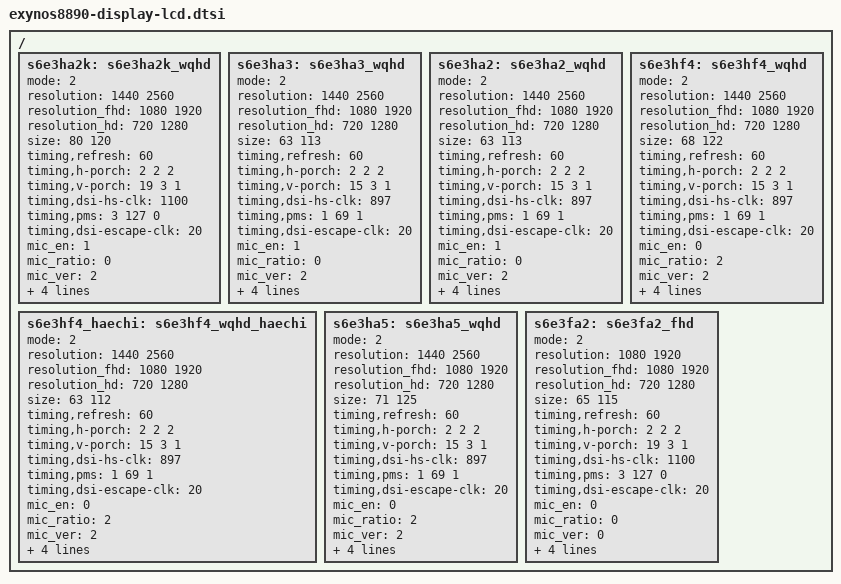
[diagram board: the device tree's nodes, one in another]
/*
 * SAMSUNG LCD Panel Device Tree Source
 *
 * Copyright (c) 2015 Samsung Electronics Co., Ltd.
 *		http://www.samsung.com
 *
 * This program is free software; you can redistribute it and/or modify
 * it under the terms of the GNU General Public License version 2 as
 * published by the Free Software Foundation.
*/

/ {
	s6e3ha2k: s6e3ha2k_wqhd {
		mode = <2>;		/* 0: video mode, 1: DP command mode, 2: MIPI command mode */
		resolution = <1440 2560>;
		resolution_fhd = <1080 1920>;
		resolution_hd = <720 1280>;
		size = <80 120>;
		timing,refresh = <60>;
		timing,h-porch = <2 2 2>;
		timing,v-porch = <19 3 1>;
		timing,dsi-hs-clk = <1100>;
		timing,pms = <3 127 0>;
		timing,dsi-escape-clk = <20>;
		mic_en = <1>;		/* 0: Disable, 1: Enable */
		mic_ratio = <0>;	/* 0: 1/2 mic, 1: 1/3 mic */
		mic_ver = <2>;		/* 0: mic v1.1, 1: v1.2, 2: v2.0 */
		type_of_ddi = <0>;	/* 0: Samsung Mobile, 1: MAGNA, 2: Normal(Etc) */
		dsc_en = <0>;		/* 0: Disable, 1: Enable */
		dsc_cnt = <0>;		/* used DSC count */
		dsc_slice_num = <0>;	/* count of dsc slice */
	};

	s6e3ha3: s6e3ha3_wqhd {
		mode = <2>;		/* 0: video mode, 1: DP command mode, 2: MIPI command mode */
		resolution = <1440 2560>;
		resolution_fhd = <1080 1920>;
		resolution_hd = <720 1280>;
		size = <63 113>;
		timing,refresh = <60>;
		timing,h-porch = <2 2 2>;
		timing,v-porch = <15 3 1>;
		timing,dsi-hs-clk = <897>;
		timing,pms = <1 69 1>;
		timing,dsi-escape-clk = <20>;
		mic_en = <1>;		/* 0: Disable, 1: Enable */
		mic_ratio = <0>;	/* 0: 1/2 mic, 1: 1/3 mic */
		mic_ver = <2>;		/* 0: mic v1.1, 1: v1.2, 2: v2.0 */
		type_of_ddi = <0>;	/* 0: Samsung Mobile, 1: MAGNA, 2: Normal(Etc) */
		dsc_en = <0>;		/* 0: Disable, 1: Enable */
		dsc_cnt = <0>;		/* used DSC count */
		dsc_slice_num = <0>;	/* count of dsc slice */
	};

	s6e3ha2: s6e3ha2_wqhd {
		mode = <2>;		/* 0: video mode, 1: DP command mode, 2: MIPI command mode */
		resolution = <1440 2560>;
		resolution_fhd = <1080 1920>;
		resolution_hd = <720 1280>;
		size = <63 113>;
		timing,refresh = <60>;
		timing,h-porch = <2 2 2>;
		timing,v-porch = <15 3 1>;
		timing,dsi-hs-clk = <897>;
		timing,pms = <1 69 1>;
		timing,dsi-escape-clk = <20>;
		mic_en = <1>;		/* 0: Disable, 1: Enable */
		mic_ratio = <0>;	/* 0: 1/2 mic, 1: 1/3 mic */
		mic_ver = <2>;		/* 0: mic v1.1, 1: v1.2, 2: v2.0 */
		type_of_ddi = <0>;	/* 0: Samsung Mobile, 1: MAGNA, 2: Normal(Etc) */
		dsc_en = <0>;		/* 0: Disable, 1: Enable */
		dsc_cnt = <0>;		/* used DSC count */
		dsc_slice_num = <0>;	/* count of dsc slice */
	};

	s6e3hf4: s6e3hf4_wqhd {
		mode = <2>;		/* 0: video mode, 1: DP command mode, 2: MIPI command mode */
		resolution = <1440 2560>;
		resolution_fhd = <1080 1920>;
		resolution_hd = <720 1280>;
		size = <68 122>;
		timing,refresh = <60>;
		timing,h-porch = <2 2 2>;
		timing,v-porch = <15 3 1>;
		timing,dsi-hs-clk = <897>;
		timing,pms = <1 69 1>;
		timing,dsi-escape-clk = <20>;
		mic_en = <0>;		/* 0: Disable, 1: Enable */
		mic_ratio = <2>;	/* 0: 1/2 mic, 1: 1/3 mic */
		mic_ver = <2>;		/* 0: mic v1.1, 1: v1.2, 2: v2.0 */
		type_of_ddi = <0>;	/* 0: Samsung Mobile, 1: MAGNA, 2: Normal(Etc) */
		dsc_en = <1>;		/* 0: Disable, 1: Enable */
		dsc_cnt = <2>;		/* used DSC count */
		dsc_slice_num = <4>;	/* count of dsc slice */
	};

	s6e3hf4_haechi: s6e3hf4_wqhd_haechi {
		mode = <2>;		/* 0: video mode, 1: DP command mode, 2: MIPI command mode */
		resolution = <1440 2560>;
		resolution_fhd = <1080 1920>;
		resolution_hd = <720 1280>;
		size = <63 112>;
		timing,refresh = <60>;
		timing,h-porch = <2 2 2>;
		timing,v-porch = <15 3 1>;
		timing,dsi-hs-clk = <897>;
		timing,pms = <1 69 1>;
		timing,dsi-escape-clk = <20>;
		mic_en = <0>;		/* 0: Disable, 1: Enable */
		mic_ratio = <2>;	/* 0: 1/2 mic, 1: 1/3 mic */
		mic_ver = <2>;		/* 0: mic v1.1, 1: v1.2, 2: v2.0 */
		type_of_ddi = <0>;	/* 0: Samsung Mobile, 1: MAGNA, 2: Normal(Etc) */
		dsc_en = <1>;		/* 0: Disable, 1: Enable */
		dsc_cnt = <2>;		/* used DSC count */
		dsc_slice_num = <4>;	/* count of dsc slice */
	};


	s6e3ha5: s6e3ha5_wqhd {
		mode = <2>;		/* 0: video mode, 1: DP command mode, 2: MIPI command mode */
		resolution = <1440 2560>;
		resolution_fhd = <1080 1920>;
		resolution_hd = <720 1280>;
		size = <71 125>;
		timing,refresh = <60>;
		timing,h-porch = <2 2 2>;
		timing,v-porch = <15 3 1>;
		timing,dsi-hs-clk = <897>;
		timing,pms = <1 69 1>;
		timing,dsi-escape-clk = <20>;
		mic_en = <0>;		/* 0: Disable, 1: Enable */
		mic_ratio = <2>;	/* 0: 1/2 mic, 1: 1/3 mic */
		mic_ver = <2>;		/* 0: mic v1.1, 1: v1.2, 2: v2.0 */
		type_of_ddi = <0>;	/* 0: Samsung Mobile, 1: MAGNA, 2: Normal(Etc) */
		dsc_en = <1>;		/* 0: Disable, 1: Enable */
		dsc_cnt = <2>;		/* used DSC count */
		dsc_slice_num = <2>;	/* count of dsc slice */
	};

	s6e3fa2: s6e3fa2_fhd {
		mode = <2>;		/* 0: video mode, 1: DP command mode, 2: MIPI command mode */
		resolution = <1080 1920>;
		resolution_fhd = <1080 1920>;
		resolution_hd = <720 1280>;
		size = <65 115>;
		timing,refresh = <60>;
		timing,h-porch = <2 2 2>;
		timing,v-porch = <19 3 1>;
		timing,dsi-hs-clk = <1100>;
		timing,pms = <3 127 0>;
		timing,dsi-escape-clk = <20>;
		mic_en = <0>;		/* 0: Disable, 1: Enable */
		mic_ratio = <0>;	/* 0: 1/2 mic, 1: 1/3 mic */
		mic_ver = <0>;		/* 0: mic v1.1, 1: v1.2, 2: v2.0 */
		type_of_ddi = <0>;	/* 0: Samsung Mobile, 1: MAGNA, 2: Normal(Etc) */
		dsc_en = <0>;		/* 0: Disable, 1: Enable */
		dsc_cnt = <0>;		/* used DSC count */
		dsc_slice_num = <0>;	/* count of dsc slice */
	};

};
